# BENCHM4 register map
File version: 1.0
Benchmark microcontroller
Registers are 32-bit, read-write, reset 0x0 unless marked. A register's access mark holds for its fields unless they carry their own. Offsets are from the block's base; lines under a group give offsets from that group; [hi:lo] are bit positions; {n}, {i} and the like mark numbered series; 'fields as' and 'values as' point back to an identical list; <NAME> marks a mode.

## Memory map
0x1FFF7000 UID size 0x10 — Unique device identifier
0x40000000 CLKCTRL size 0x400 — Clock control
0x40001000 GPIOA size 0x400 — General-purpose I/O port
0x40001400 GPIOB size 0x400
0x40002000 UART0 size 0x400 — Serial port
0x40003000 TIMER0 size 0x400 — General-purpose timer
0x40003400 TIMER1 size 0x400
0x40004000 WDOG size 0x400 — Watchdog
0x40009000 OTP size 0x100 — One-time-programmable fuse block

## CLKCTRL — Clock control
Base 0x40000000
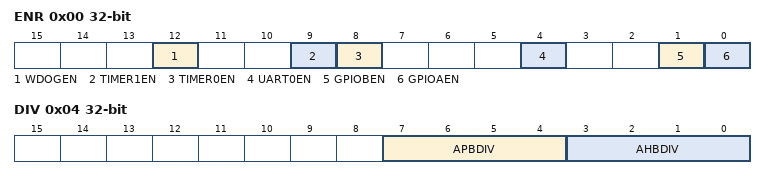
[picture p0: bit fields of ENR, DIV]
0x00 ENR — Peripheral clock enable
  [12] WDOGEN, [9] TIMER1EN, [8] TIMER0EN, [4] UART0EN, [1] GPIOBEN, [0] GPIOAEN
0x04 DIV — Bus clock dividers
  [7:4] APBDIV, [3:0] AHBDIV
0x08 STAT ro — Clock status
  [0] READY

## GPIOA — General-purpose I/O port
Base 0x40001000
Same registers: GPIOB 0x40001400
0x00 MODE — Pin direction, one bit per pin
0x04 OUT — Output levels
0x08 IN ro — Input levels
0x0C SET wo — Set output bits
0x10 CLR wo — Clear output bits

## UART0 — Serial port
Base 0x40002000
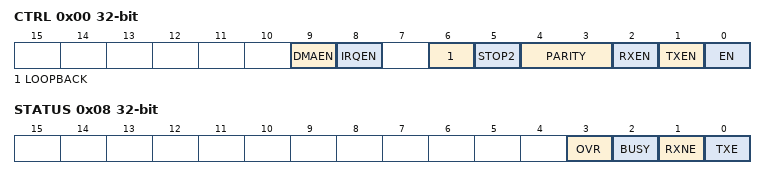
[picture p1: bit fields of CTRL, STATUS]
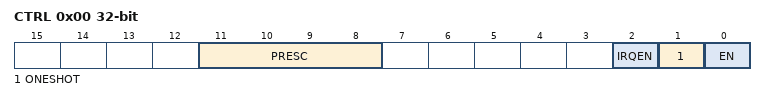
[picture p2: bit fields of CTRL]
0x00 CTRL — Control
  [9] DMAEN
  [8] IRQEN
  [6] LOOPBACK
  [5] STOP2
  [4:3] PARITY
    0=None; 1=Odd; 2=Even
  [2] RXEN
  [1] TXEN
  [0] EN
0x04 BAUD — Baud rate divisor
  [15:0] DIV
0x08 STATUS
  [3] OVR, [2] BUSY ro, [1] RXNE ro, [0] TXE ro
0x0C DATA — Transmit and receive data
  [7:0] DATA

## TIMER0 — General-purpose timer
Base 0x40003000
Same registers: TIMER1 0x40003400
0x00 CTRL — Control
  [11:8] PRESC, [2] IRQEN, [1] ONESHOT, [0] EN
0x04 LOAD — Reload value
0x08 COUNT ro — Current count
0x0C INTCLR wo — Interrupt clear

## WDOG — Watchdog
Base 0x40004000
0x00 KEY wo — Refresh key
0x04 RELOAD — Timeout
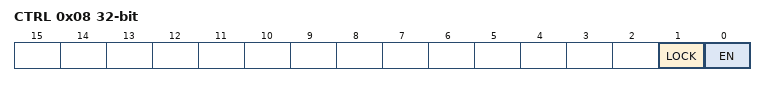
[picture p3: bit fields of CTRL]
0x08 CTRL — Control
  [1] LOCK, [0] EN

## OTP — One-time-programmable fuse block
Base 0x40009000
0x00 STATUS ro — Fuse controller status
0x10 MINVER ro — Monotonic minimum firmware version counter
0x14 SERIAL ro — Board serial number

## UID — Unique device identifier
Base 0x1FFF7000
{0x0+4i} UID{i} ro (i=0..2) — Unique ID bits {32i+31}:{32i}

## Notices in the file
SPDX-License-Identifier: Apache-2.0
